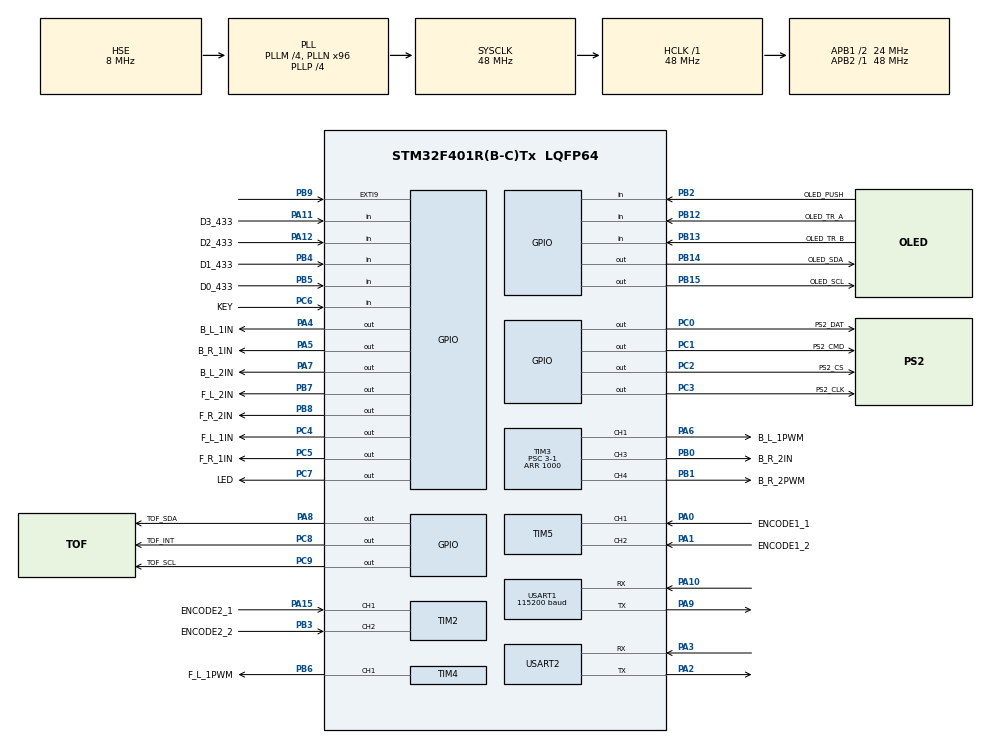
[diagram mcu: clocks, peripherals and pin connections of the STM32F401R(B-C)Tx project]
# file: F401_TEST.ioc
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ADC1.Channel-0\#ChannelRegularConversion=ADC_CHANNEL_VBAT
ADC1.NbrOfConversionFlag=1
ADC1.Rank-0\#ChannelRegularConversion=1
ADC1.SamplingTime-0\#ChannelRegularConversion=ADC_SAMPLETIME_3CYCLES
ADC1.master=1
Dma.Request0=USART1_RX
Dma.Request1=USART1_TX
Dma.Request2=USART2_RX
Dma.Request3=USART2_TX
Dma.USART1_RX.0.Direction=DMA_PERIPH_TO_MEMORY
Dma.USART1_RX.0.FIFOMode=DMA_FIFOMODE_DISABLE
Dma.USART1_RX.0.Instance=DMA2_Stream2
Dma.USART1_RX.0.MemDataAlignment=DMA_MDATAALIGN_BYTE
Dma.USART1_RX.0.MemInc=DMA_MINC_ENABLE
Dma.USART1_RX.0.Mode=DMA_NORMAL
Dma.USART1_RX.0.PeriphDataAlignment=DMA_PDATAALIGN_BYTE
Dma.USART1_RX.0.PeriphInc=DMA_PINC_DISABLE
Dma.USART1_RX.0.Priority=DMA_PRIORITY_LOW
Dma.USART1_TX.1.Direction=DMA_MEMORY_TO_PERIPH
Dma.USART1_TX.1.FIFOMode=DMA_FIFOMODE_DISABLE
Dma.USART1_TX.1.Instance=DMA2_Stream7
Dma.USART1_TX.1.MemDataAlignment=DMA_MDATAALIGN_BYTE
Dma.USART1_TX.1.MemInc=DMA_MINC_ENABLE
Dma.USART1_TX.1.Mode=DMA_NORMAL
Dma.USART1_TX.1.PeriphDataAlignment=DMA_PDATAALIGN_BYTE
Dma.USART1_TX.1.PeriphInc=DMA_PINC_DISABLE
Dma.USART1_TX.1.Priority=DMA_PRIORITY_LOW
Dma.USART2_RX.2.Direction=DMA_PERIPH_TO_MEMORY
Dma.USART2_RX.2.FIFOMode=DMA_FIFOMODE_DISABLE
Dma.USART2_RX.2.Instance=DMA1_Stream5
Dma.USART2_RX.2.MemDataAlignment=DMA_MDATAALIGN_BYTE
Dma.USART2_RX.2.MemInc=DMA_MINC_ENABLE
Dma.USART2_RX.2.Mode=DMA_NORMAL
Dma.USART2_RX.2.PeriphDataAlignment=DMA_PDATAALIGN_BYTE
Dma.USART2_RX.2.PeriphInc=DMA_PINC_DISABLE
Dma.USART2_RX.2.Priority=DMA_PRIORITY_LOW
Dma.USART2_TX.3.Direction=DMA_MEMORY_TO_PERIPH
Dma.USART2_TX.3.FIFOMode=DMA_FIFOMODE_DISABLE
Dma.USART2_TX.3.Instance=DMA1_Stream6
Dma.USART2_TX.3.MemDataAlignment=DMA_MDATAALIGN_BYTE
Dma.USART2_TX.3.MemInc=DMA_MINC_ENABLE
Dma.USART2_TX.3.Mode=DMA_NORMAL
Dma.USART2_TX.3.PeriphDataAlignment=DMA_PDATAALIGN_BYTE
Dma.USART2_TX.3.PeriphInc=DMA_PINC_DISABLE
Dma.USART2_TX.3.Priority=DMA_PRIORITY_LOW
Mcu.Family=STM32F4
Mcu.Name=STM32F401R(B-C)Tx
Mcu.Package=LQFP64
NVIC.DMA1_Stream5_IRQn=true\:0\:0\:false\:false\:true\:false\:true\:true
NVIC.DMA1_Stream6_IRQn=true\:0\:0\:false\:false\:true\:false\:true\:true
NVIC.DMA2_Stream2_IRQn=true\:0\:0\:false\:false\:true\:false\:true\:true
NVIC.DMA2_Stream7_IRQn=true\:0\:0\:false\:false\:true\:false\:true\:true
NVIC.EXTI9_5_IRQn=true\:0\:0\:false\:false\:true\:true\:true\:true
NVIC.PriorityGroup=NVIC_PRIORITYGROUP_4
NVIC.TIM1_UP_TIM10_IRQn=true\:0\:0\:false\:false\:true\:true\:true\:true
PA0-WKUP.GPIO_Label=ENCODE1_1
PA0-WKUP.Signal=S_TIM5_CH1
PA1.GPIO_Label=ENCODE1_2
PA1.Signal=S_TIM5_CH2
PA10.Mode=Asynchronous
PA10.Signal=USART1_RX
PA11.GPIO_Label=D3_433
PA11.Signal=GPIO_Input
PA12.GPIO_Label=D2_433
PA12.Signal=GPIO_Input
PA13.Mode=Serial_Wire
PA13.Signal=SYS_JTMS-SWDIO
PA14.Mode=Serial_Wire
PA14.Signal=SYS_JTCK-SWCLK
PA15.GPIO_Label=ENCODE2_1
PA15.Signal=S_TIM2_CH1_ETR
PA2.Mode=Asynchronous
PA2.Signal=USART2_TX
PA3.Mode=Asynchronous
PA3.Signal=USART2_RX
PA4.GPIO_Label=B_L_1IN
PA4.Signal=GPIO_Output
PA5.GPIO_Label=B_R_1IN
PA5.Signal=GPIO_Output
PA6.GPIO_Label=B_L_1PWM
PA6.Signal=S_TIM3_CH1
PA7.GPIO_Label=B_L_2IN
PA7.Signal=GPIO_Output
PA8.GPIO_Label=TOF_SDA
PA8.Signal=GPIO_Output
PA9.Mode=Asynchronous
PA9.Signal=USART1_TX
PB0.GPIO_Label=B_R_2IN
PB0.Signal=S_TIM3_CH3
PB1.GPIO_Label=B_R_2PWM
PB1.Signal=S_TIM3_CH4
PB12.GPIO_Label=OLED_TR_A
PB12.Signal=GPIO_Input
PB13.GPIO_Label=OLED_TR_B
PB13.Signal=GPIO_Input
PB14.GPIO_Label=OLED_SDA
PB14.Signal=GPIO_Output
PB15.GPIO_Label=OLED_SCL
PB15.Signal=GPIO_Output
PB2.GPIO_Label=OLED_PUSH
PB2.Signal=GPIO_Input
PB3.GPIO_Label=ENCODE2_2
PB3.Signal=S_TIM2_CH2
PB4.GPIO_Label=D1_433
PB4.Signal=GPIO_Input
PB5.GPIO_Label=D0_433
PB5.Signal=GPIO_Input
PB6.GPIO_Label=F_L_1PWM
PB6.Signal=S_TIM4_CH1
PB7.GPIO_Label=F_L_2IN
PB7.Signal=GPIO_Output
PB8.GPIO_Label=F_R_2IN
PB8.Signal=GPIO_Output
PB9.GPIO_ModeDefaultEXTI=GPIO_MODE_IT_FALLING
PB9.GPIO_PuPd=GPIO_PULLUP
PB9.Signal=GPXTI9
PC0.GPIO_Label=PS2_DAT
PC0.Signal=GPIO_Output
PC1.GPIO_Label=PS2_CMD
PC1.Signal=GPIO_Output
PC14-OSC32_IN.Mode=LSE-External-Oscillator
PC14-OSC32_IN.Signal=RCC_OSC32_IN
PC15-OSC32_OUT.Mode=LSE-External-Oscillator
PC15-OSC32_OUT.Signal=RCC_OSC32_OUT
PC2.GPIO_Label=PS2_CS
PC2.Signal=GPIO_Output
PC3.GPIO_Label=PS2_CLK
PC3.Signal=GPIO_Output
PC4.GPIO_Label=F_L_1IN
PC4.Signal=GPIO_Output
PC5.GPIO_Label=F_R_1IN
PC5.Signal=GPIO_Output
PC6.GPIO_Label=KEY
PC6.Signal=GPIO_Input
PC7.GPIO_Label=LED
PC7.Signal=GPIO_Output
PC8.GPIO_Label=TOF_INT
PC8.Signal=GPIO_Output
PC9.GPIO_Label=TOF_SCL
PC9.Signal=GPIO_Output
PH0\ -\ OSC_IN.Mode=HSE-External-Oscillator
PH0\ -\ OSC_IN.Signal=RCC_OSC_IN
PH1\ -\ OSC_OUT.Mode=HSE-External-Oscillator
PH1\ -\ OSC_OUT.Signal=RCC_OSC_OUT
ProjectManager.HeapSize=0x200
ProjectManager.StackSize=0x400
ProjectManager.TargetToolchain=MDK-ARM V5.32
RCC.48MHZClocksFreq_Value=48000000
RCC.AHBFreq_Value=48000000
RCC.APB1CLKDivider=RCC_HCLK_DIV2
RCC.APB1Freq_Value=24000000
RCC.APB1TimFreq_Value=48000000
RCC.APB2Freq_Value=48000000
RCC.APB2TimFreq_Value=48000000
RCC.CortexFreq_Value=48000000
RCC.HCLKFreq_Value=48000000
RCC.HSE_VALUE=8000000
RCC.HSI_VALUE=16000000
RCC.PLLM=4
RCC.PLLN=96
RCC.PLLP=RCC_PLLP_DIV4
RCC.PLLSourceVirtual=RCC_PLLSOURCE_HSE
RCC.RCC_RTC_Clock_Source=RCC_RTCCLKSOURCE_LSE
RCC.RCC_RTC_Clock_SourceVirtual=RCC_RTCCLKSOURCE_LSE
RCC.SYSCLKFreq_VALUE=48000000
RCC.SYSCLKSource=RCC_SYSCLKSOURCE_PLLCLK
RCC.VCOOutputFreq_Value=192000000
SH.S_TIM2_CH1_ETR.0=TIM2_CH1,Encoder_Interface
SH.S_TIM2_CH2.0=TIM2_CH2,Encoder_Interface
SH.S_TIM3_CH1.0=TIM3_CH1,PWM Generation1 CH1
SH.S_TIM3_CH3.0=TIM3_CH3,PWM Generation3 CH3
SH.S_TIM3_CH4.0=TIM3_CH4,PWM Generation4 CH4
SH.S_TIM4_CH1.0=TIM4_CH1,PWM Generation1 CH1
SH.S_TIM5_CH1.0=TIM5_CH1,Encoder_Interface
SH.S_TIM5_CH2.0=TIM5_CH2,Encoder_Interface
TIM1.Period=100-1
TIM1.Prescaler=48-1
TIM3.Channel-PWM\ Generation1\ CH1=TIM_CHANNEL_1
TIM3.Channel-PWM\ Generation3\ CH3=TIM_CHANNEL_3
TIM3.Channel-PWM\ Generation4\ CH4=TIM_CHANNEL_4
TIM3.OCMode_PWM-PWM\ Generation1\ CH1=TIM_OCMODE_PWM1
TIM3.Period=1000
TIM3.Prescaler=3-1
TIM4.Channel-PWM\ Generation1\ CH1=TIM_CHANNEL_1
TIM4.Period=1000
TIM4.Prescaler=3-1
USART1.BaudRate=115200
USART1.Parity=PARITY_NONE
USART1.StopBits=STOPBITS_1
USART1.VirtualMode=VM_ASYNC
USART2.VirtualMode=VM_ASYNC
VP_ADC1_Vbat_Input.Mode=IN-Vbat
VP_RTC_VS_RTC_Activate.Mode=RTC_Enabled
VP_TIM1_VS_ClockSourceINT.Mode=Internal
VP_TIM3_VS_ClockSourceINT.Mode=Internal
VP_TIM4_VS_ClockSourceINT.Mode=Internal
board=custom

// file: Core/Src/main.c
/* USER CODE BEGIN Header */
/**
  ******************************************************************************
  * @file           : main.c
  * @brief          : 主程序文�?
  ******************************************************************************
  * @attention
  *
  * 版权�?�? (c) 2024 意法半导�?
  * 保留�?有权�?
  *
  * 本软件的许可条款可在本软件组件根目录下的 LICENSE 文件中找�?
  * 如果本软件未附带 LICENSE 文件，则按原样提�?
  *
  ******************************************************************************
  */
/* USER CODE END Header */
#include "main.h"
#include "adc.h"
#include "dma.h"
#include "rtc.h"
#include "tim.h"
#include "usart.h"
#include "gpio.h"

/* USER CODE BEGIN Includes */

#include "app_main.h"

/* USER CODE END Includes */

void SystemClock_Config(void);

int main(void)
{

  /* MCU Configuration--------------------------------------------------------*/

  /* Reset of all peripherals, Initializes the Flash interface and the Systick. */
  HAL_Init();

  /* Configure the system clock */
  SystemClock_Config();

  /* Initialize all configured peripherals */
  MX_GPIO_Init();
  MX_DMA_Init();
  MX_TIM3_Init();
  MX_TIM4_Init();
  MX_USART1_UART_Init();
  MX_USART2_UART_Init();
  MX_RTC_Init();
  MX_TIM1_Init();
  MX_TIM2_Init();
  MX_TIM5_Init();
  MX_ADC1_Init();
  /* USER CODE BEGIN 2 */
  App_Init();
  /* USER CODE END 2 */

  /* Infinite loop */
  while (1)
  {

    /* USER CODE BEGIN 3 */
	App_Loop();
  }
  /* USER CODE END 3 */
}

void SystemClock_Config(void)
{
  RCC_OscInitTypeDef RCC_OscInitStruct = {0};
  RCC_ClkInitTypeDef RCC_ClkInitStruct = {0};

  /** Configure the main internal regulator output voltage
  */
  __HAL_RCC_PWR_CLK_ENABLE();
  __HAL_PWR_VOLTAGESCALING_CONFIG(PWR_REGULATOR_VOLTAGE_SCALE2);

  /** Initializes the RCC Oscillators according to the specified parameters
  * in the RCC_OscInitTypeDef structure.
  */
  RCC_OscInitStruct.OscillatorType = RCC_OSCILLATORTYPE_HSE|RCC_OSCILLATORTYPE_LSE;
  RCC_OscInitStruct.HSEState = RCC_HSE_ON;
  RCC_OscInitStruct.LSEState = RCC_LSE_ON;
  RCC_OscInitStruct.PLL.PLLState = RCC_PLL_ON;
  RCC_OscInitStruct.PLL.PLLSource = RCC_PLLSOURCE_HSE;
  RCC_OscInitStruct.PLL.PLLM = 4;
  RCC_OscInitStruct.PLL.PLLN = 96;
  RCC_OscInitStruct.PLL.PLLP = RCC_PLLP_DIV4;
  RCC_OscInitStruct.PLL.PLLQ = 4;
  if (HAL_RCC_OscConfig(&RCC_OscInitStruct) != HAL_OK)
  {
    Error_Handler();
  }

  /** Initializes the CPU, AHB and APB buses clocks
  */
  RCC_ClkInitStruct.ClockType = RCC_CLOCKTYPE_HCLK|RCC_CLOCKTYPE_SYSCLK
                              |RCC_CLOCKTYPE_PCLK1|RCC_CLOCKTYPE_PCLK2;
  RCC_ClkInitStruct.SYSCLKSource = RCC_SYSCLKSOURCE_PLLCLK;
  RCC_ClkInitStruct.AHBCLKDivider = RCC_SYSCLK_DIV1;
  RCC_ClkInitStruct.APB1CLKDivider = RCC_HCLK_DIV2;
  RCC_ClkInitStruct.APB2CLKDivider = RCC_HCLK_DIV1;

  if (HAL_RCC_ClockConfig(&RCC_ClkInitStruct, FLASH_LATENCY_1) != HAL_OK)
  {
    Error_Handler();
  }
}

void Error_Handler(void)
{
  /* USER CODE BEGIN Error_Handler_Debug */
  /* 用户可以添加自己的实现来报告HAL错误返回状�?? */
  __disable_irq();
  while (1)
  {
  }
  /* USER CODE END Error_Handler_Debug */
}

#ifdef  USE_FULL_ASSERT
/**
  * @brief  Reports the name of the source file and the source line number
  *         where the assert_param error has occurred.
  * @param  file: pointer to the source file name
  * @param  line: assert_param error line source number
  * @retval None
  */
void assert_failed(uint8_t *file, uint32_t line)
{
  /* USER CODE BEGIN 6 */
  /* 用户可以添加自己的实现来报告文件名和行号
     例如: printf("参数值错�?: 文件 %s �? %d 行\r\n", file, line) */
  /* USER CODE END 6 */
}
#endif /* USE_FULL_ASSERT */
